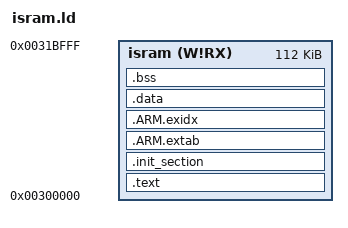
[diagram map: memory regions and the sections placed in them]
/****************************************************************************
 * configs/sama5d3-xplained/scripts/isram.ld
 *
 *   Copyright (C) 2014 Gregory Nutt. All rights reserved.
 *   Author: Gregory Nutt <gnutt@nuttx.org>
 *
 * Redistribution and use in source and binary forms, with or without
 * modification, are permitted provided that the following conditions
 * are met:
 *
 * 1. Redistributions of source code must retain the above copyright
 *    notice, this list of conditions and the following disclaimer.
 * 2. Redistributions in binary form must reproduce the above copyright
 *    notice, this list of conditions and the following disclaimer in
 *    the documentation and/or other materials provided with the
 *    distribution.
 * 3. Neither the name NuttX nor the names of its contributors may be
 *    used to endorse or promote products derived from this software
 *    without specific prior written permission.
 *
 * THIS SOFTWARE IS PROVIDED BY THE COPYRIGHT HOLDERS AND CONTRIBUTORS
 * "AS IS" AND ANY EXPRESS OR IMPLIED WARRANTIES, INCLUDING, BUT NOT
 * LIMITED TO, THE IMPLIED WARRANTIES OF MERCHANTABILITY AND FITNESS
 * FOR A PARTICULAR PURPOSE ARE DISCLAIMED. IN NO EVENT SHALL THE
 * COPYRIGHT OWNER OR CONTRIBUTORS BE LIABLE FOR ANY DIRECT, INDIRECT,
 * INCIDENTAL, SPECIAL, EXEMPLARY, OR CONSEQUENTIAL DAMAGES (INCLUDING,
 * BUT NOT LIMITED TO, PROCUREMENT OF SUBSTITUTE GOODS OR SERVICES; LOSS
 * OF USE, DATA, OR PROFITS; OR BUSINESS INTERRUPTION) HOWEVER CAUSED
 * AND ON ANY THEORY OF LIABILITY, WHETHER IN CONTRACT, STRICT
 * LIABILITY, OR TORT (INCLUDING NEGLIGENCE OR OTHERWISE) ARISING IN
 * ANY WAY OUT OF THE USE OF THIS SOFTWARE, EVEN IF ADVISED OF THE
 * POSSIBILITY OF SUCH DAMAGE.
 *
 ****************************************************************************/

/* The SAMA5D36 has 128 KB of ISRAM beginning at virtual address 0x0030:0000.
 *
 * Vectors in low memory are assumed and 16KB of ISRAM is reserved at the
 * high end of ISRAM for the page table.
 */

MEMORY
{
	isram (W!RX) : ORIGIN = 0x300000, LENGTH = 128K - 16K
}

OUTPUT_FORMAT("elf32-littlearm", "elf32-littlearm", "elf32-littlearm")
OUTPUT_ARCH(arm)
ENTRY(entry)
ENTRY(_stext)

SECTIONS
{
	.text : {
		_stext = ABSOLUTE(.);
		*(.vectors)
		*(.text .text.*)
		*(.fixup)
		*(.gnu.warning)
		*(.rodata .rodata.*)
		*(.gnu.linkonce.t.*)
		*(.glue_7)
		*(.glue_7t)
		*(.got)
		*(.gcc_except_table)
		*(.gnu.linkonce.r.*)
		*(.ARM.extab*)
		*(.gnu.linkonce.armextab.*)
		_etext = ABSOLUTE(.);
	} > isram

	.init_section : {
		_sinit = ABSOLUTE(.);
		*(.init_array .init_array.*)
		_einit = ABSOLUTE(.);
	} > isram

	.ARM.extab : {
		*(.ARM.extab*)
	} > isram

	/* .ARM.exidx is sorted, so has to go in its own output section.  */

	PROVIDE_HIDDEN (__exidx_start = .);
	.ARM.exidx :
	{
		*(.ARM.exidx* .gnu.linkonce.armexidx.*)
	} > isram
	PROVIDE_HIDDEN (__exidx_end = .);

	.data : {
		_sdata = ABSOLUTE(.);
		*(.data .data.*)
		*(.gnu.linkonce.d.*)
		CONSTRUCTORS
		_edata = ABSOLUTE(.);
	} > isram

	.bss : {
		_sbss = ABSOLUTE(.);
		*(.bss .bss.*)
		*(.gnu.linkonce.b.*)
		*(COMMON)
		_ebss = ABSOLUTE(.);
	} > isram

	/* Stabs debugging sections. */
	.stab 0 : { *(.stab) }
	.stabstr 0 : { *(.stabstr) }
	.stab.excl 0 : { *(.stab.excl) }
	.stab.exclstr 0 : { *(.stab.exclstr) }
	.stab.index 0 : { *(.stab.index) }
	.stab.indexstr 0 : { *(.stab.indexstr) }
	.comment 0 : { *(.comment) }
	.debug_abbrev 0 : { *(.debug_abbrev) }
	.debug_info 0 : { *(.debug_info) }
	.debug_line 0 : { *(.debug_line) }
	.debug_pubnames 0 : { *(.debug_pubnames) }
	.debug_aranges 0 : { *(.debug_aranges) }
}
